# FM33FG0XXA register map
File version: 1.0
CPU: SC000 r1p0, little endian, MPU, no FPU, 3 interrupt priority bits
Registers are 32-bit, read-only, reset 0x0 unless marked. A register's access mark holds for its fields unless they carry their own. Offsets are from the block's base; [hi:lo] are bit positions.

## UART0 — UART0 module information
Base 0x40016800
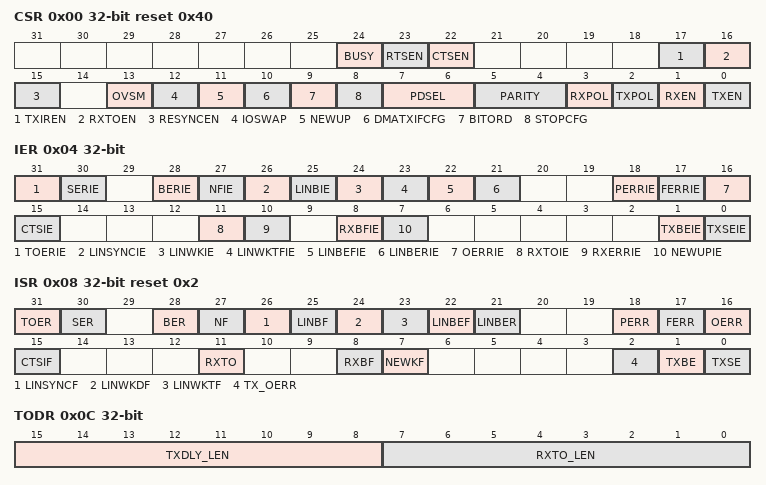
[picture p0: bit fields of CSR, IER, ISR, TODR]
0x00 CSR access per field reset 0x40 — UART Control Status Register
  [24] BUSY ro — BUSY field description
  [23] RTSEN rw — RTSEN field description
  [22] CTSEN rw — CTSEN field description
  [17] TXIREN rw — TXIREN field description
  [16] RXTOEN rw — RXTOEN field description
  [15] RESYNCEN rw — RESYNCEN field description
  [13] OVSM rw — OVSM field description
  [12] IOSWAP rw — IOSWAP field description
  [11] NEWUP rw — NEWUP field description
  [10] DMATXIFCFG rw — DMATXIFCFG field description
  [9] BITORD rw — BITORD field description
  [8] STOPCFG rw — STOPCFG field description
  [7:6] PDSEL rw — PDSEL field description
  [5:4] PARITY rw — PARITY field description
  [3] RXPOL rw — RXPOL field description
  [2] TXPOL rw — TXPOL field description
  [1] RXEN rw — RXEN field description
  [0] TXEN rw — TXEN field description
0x04 IER rw — UART Interrupt Enable Register
  [31] TOERIE — TOERIE field description
  [30] SERIE — SERIE field description
  [28] BERIE — BERIE field description
  [27] NFIE — NFIE field description
  [26] LINSYNCIE — LINSYNCIE field description
  [25] LINBIE — LINBIE field description
  [24] LINWKIE — LINWKIE field description
  [23] LINWKTFIE — LINWKTFIE field description
  [22] LINBEFIE — LINBEFIE field description
  [21] LINBERIE — LINBERIE field description
  [18] PERRIE — PERRIE field description
  [17] FERRIE — FERRIE field description
  [16] OERRIE — OERRIE field description
  [15] CTSIE — CTSIE field description
  [11] RXTOIE — RXTOIE field description
  [10] RXERRIE — RXERRIE field description
  [8] RXBFIE — RXBFIE field description
  [7] NEWUPIE — NEWUPIE field description
  [1] TXBEIE — TXBEIE field description
  [0] TXSEIE — TXSEIE field description
0x08 ISR access per field reset 0x2 — UART Interrupt Status Register
  [31] TOER rw — TOER field description
  [30] SER rw — SER field description
  [28] BER rw — BER field description
  [27] NF rw — NF field description
  [26] LINSYNCF rw — LINSYNCF field description
  [25] LINBF rw — LINBF field description
  [24] LINWKDF rw — LINWKDF field description
  [23] LINWKTF rw — LINWKTF field description
  [22] LINBEF rw — LINBEF field description
  [21] LINBER rw — LINBER field description
  [18] PERR rw — PERR field description
  [17] FERR rw — FERR field description
  [16] OERR rw — OERR field description
  [15] CTSIF rw — CTSIF field description
  [11] RXTO rw — RXTO field description
  [8] RXBF rw — RXBF field description
  [7] NEWKF rw — NEWKF field description
  [2] TX_OERR rw — TX_OERR field description
  [1] TXBE ro — TXBE field description
  [0] TXSE rw — TXSE field description
0x0C TODR rw — UART Time-Out and Delay Register
  [15:8] TXDLY_LEN — TXDLY_LEN field description
  [7:0] RXTO_LEN — RXTO_LEN field description
0x10 RXBUF — UART Receive Buffer
  [8:0] RXBUF — RXBUF field description
0x14 TXBUF wo — UART Transmit Buffer
  [8:0] TXBUF — TXBUF field description
0x18 BGR rw reset 0x341 — UART Baud rate Generator Register
  [15:0] SPBRG — SPBRG field description
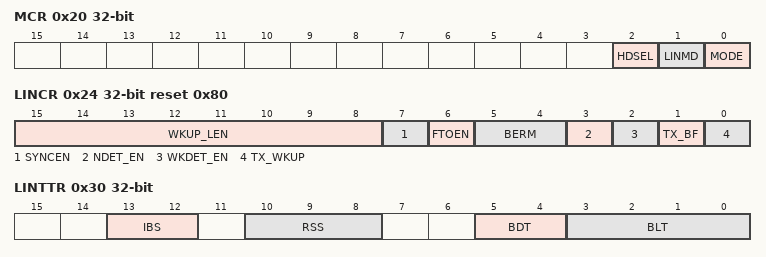
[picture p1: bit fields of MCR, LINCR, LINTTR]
0x20 MCR rw — UART Mode Control Register
  [2] HDSEL — HDSEL field description
  [1] LINMD — LINMD field description
  [0] MODE — MODE field description
0x24 LINCR rw reset 0x80 — UART LIN Control Register
  [15:8] WKUP_LEN — WKUP_LEN field description
  [7] SYNCEN — SYNCEN field description
  [6] FTOEN — FTOEN field description
  [5:4] BERM — BERM field description
  [3] NDET_EN — NDET_EN field description
  [2] WKDET_EN — WKDET_EN field description
  [1] TX_BF — TX_BF field description
  [0] TX_WKUP — TX_WKUP field description
0x28 LINBSR — UART LIN Baud Sync Register
  [19:0] BAUD_SYNC — BAUD_SYNC field description
0x2C LINFTR rw — UART LIN Frame Timeout Register
  [11:0] FTO — FTO field description
0x30 LINTTR rw — UART LIN Transmit Timing Register
  [13:12] IBS — IBS field description
  [10:8] RSS — RSS field description
  [5:4] BDT — BDT field description
  [3:0] BLT — BLT field description
0x34 LINPSR — UARTLINPre-sync baud register
  [19:0] PRE_SYNC — PRE_SYNC field description
0x38 LINBKR — UARTLINBreak counter register
  [11:0] BREAK_LEN — BREAK_LEN field description
0x80 LINSSCR rw — LIN Self-test Switch Control Register
  [1:0] LINSTC — LINSTC field description

## UART1 — UART1 module information
Base 0x40017000
Same registers: UART2 0x40017400, UART3 0x40017800
Registers as UART0, without LINSSCR.
